# psoc4000s register map
Vendor: Infineon Technologies; Series: PSOC4000S; File version: 1.0
CPU: CM0PLUS r0p1, little endian, MPU, no FPU, VTOR, 2 interrupt priority bits, 16 interrupts
Registers are 32-bit, read-write, reset 0x0 unless marked. A register's access mark holds for its fields unless they carry their own. Offsets are from the block's base; [hi:lo] are bit positions; 'fields as' and 'values as' point back to an identical list; <NAME> marks a mode.

## LPCOMP — Low Power Comparators
Base 0x400C0000
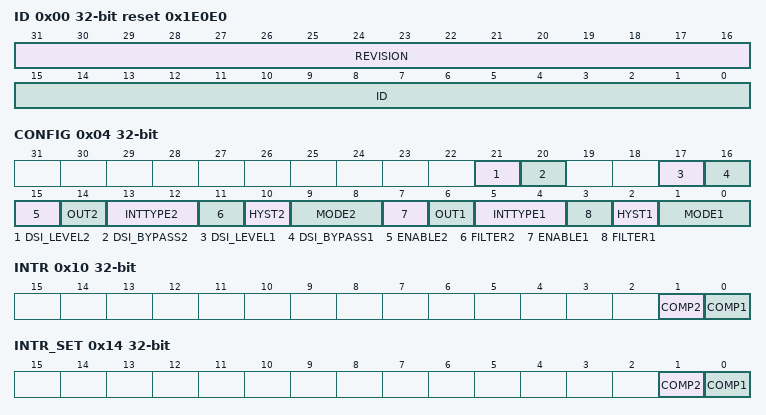
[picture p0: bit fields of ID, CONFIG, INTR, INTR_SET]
0x00 ID ro reset 0x1E0E0 — ID & Revision
  [31:16] REVISION — the version number is 0x0001
  [15:0] ID — the ID of LPCOMP peripheral is 0xE0E0
0x04 CONFIG — LPCOMP Configuration Register
  [21] DSI_LEVEL2 — Opamp2 comparator DSI (trigger) out level : 0=pulse, 1=level
  [20] DSI_BYPASS2 — Opamp2 bypass comparator output synchronization for DSI output: 0=synchronize (level or pulse), 1=bypass (output async) Note that in DeepSleep mode this bit needs to be set to observe the DSI output on the dedicated pin.
  [17] DSI_LEVEL1 — Opamp1 comparator DSI (trigger) out level : 0=pulse, 1=level
  [16] DSI_BYPASS1 — Opamp1 bypass comparator output synchronization for DSI output: 0=synchronize (level or pulse), 1=bypass (output async) Note that in DeepSleep mode this bit needs to be set to observe the DSI output on the dedicated pin.
  [15] ENABLE2 — Enable comparator #2
  [14] OUT2 ro — Current output value of the comparator.
  [13:12] INTTYPE2 — Sets which edge will trigger an IRQ
    0=DISABLE (Disabled, no interrupts will be detected); 1=RISING (Rising edge); 2=FALLING (Falling edge); 3=BOTH (Both rising and falling edges)
  [11] FILTER2
  [10] HYST2 — Add 10mV hysteresis to the comparator - 0: Enable Hysteresis - 1: Disable Hysteresis
  [9:8] MODE2 — Operating mode for the comparator
    0=SLOW (Slow operating mode (uses less power, <50uA)); 1=FAST (Fast operating mode (uses more power, <400uA)); 2=ULP (Ultra low power operting mode (uses ~2-4uA))
  [7] ENABLE1 — Enable comparator #1
  [6] OUT1 ro — Current output value of the comparator.
  [5:4] INTTYPE1 — Sets which edge will trigger an IRQ
    values as INTTYPE2
  [3] FILTER1
  [2] HYST1 — Add 10mV hysteresis to the comparator - 0: Enable Hysteresis - 1: Disable Hysteresis
  [1:0] MODE1 — Operating mode for the comparator
    values as MODE2
0x10 INTR — LPCOMP Interrupt request register
  [1] COMP2 write-1-clears — Comparator 2 Interrupt: hardware sets this interrupt when comparator 0 triggers. Write with '1' to clear bit.
  [0] COMP1 write-1-clears — Comparator 1 Interrupt: hardware sets this interrupt when comparator 0 triggers. Write with '1' to clear bit.
0x14 INTR_SET — LPCOMP Interrupt set register
  [1] COMP2 write-1-sets — Write with '1' to set corresponding bit in interrupt request register.
  [0] COMP1 write-1-sets — Write with '1' to set corresponding bit in interrupt request register.
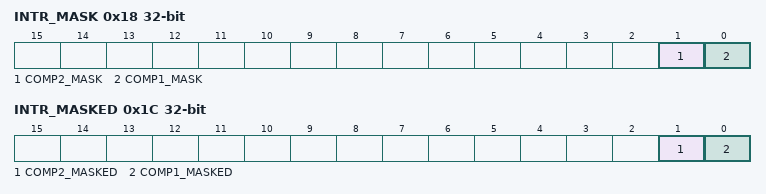
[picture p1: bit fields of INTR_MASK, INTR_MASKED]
0x18 INTR_MASK — LPCOMP Interrupt request mask
  [1] COMP2_MASK — Mask bit for corresponding bit in interrupt request register.
  [0] COMP1_MASK — Mask bit for corresponding bit in interrupt request register.
0x1C INTR_MASKED ro — LPCOMP Interrupt request masked
  [1] COMP2_MASKED — Logical and of corresponding request and mask bits.
  [0] COMP1_MASKED — Logical and of corresponding request and mask bits.
0xFF00 TRIM1 — LPCOMP Trim Register
  [4:0] COMP1_TRIMA — Trim A for Comparator #1
0xFF04 TRIM2 — LPCOMP Trim Register
  [4:0] COMP1_TRIMB — Trim B for Comparator #1
0xFF08 TRIM3 — LPCOMP Trim Register
  [4:0] COMP2_TRIMA — Trim A for Comparator #2
0xFF0C TRIM4 — LPCOMP Trim Register
  [4:0] COMP2_TRIMB — Trim B for Comparator #2

## SPCIF — Flash Control Interface
Base 0x40110000
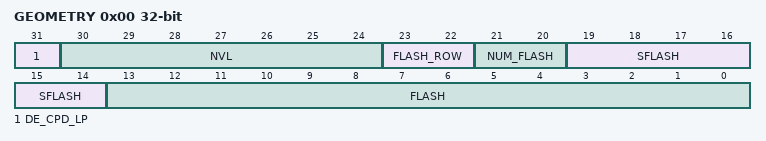
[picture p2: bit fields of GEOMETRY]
0x00 GEOMETRY (reset mask 0x80000000) — Flash/NVL geometry information
  [31] DE_CPD_LP — 0': SRAM busy wait loop has not been copied. '1': Busy wait loop has been written into SRAM.
  [30:24] NVL ro — NVLatch size in Byte multiples (chip dependent): '0': 0 Bytes '1': 1 Byte ... '127': 127 Bytes
  [23:22] FLASH_ROW ro — Page size in 64 Byte multiples (chip dependent): '0': 64 byte '1': 128 byte '2': 192 byte '3': 256 byte The page size is used to determine the number of Bytes in a page for Flash page based operations (e.g. PGM_PAGE). Note: the field name FLASH_ROW is misleading, as this field specifies the number of Bytes in a page, rather than the number of Bytes in a row. In a single plane flash macro architecture, a page consists of a single row. However, in a multi plane flash macro architecture, a page consists of multiple rows from different planes.
  [21:20] NUM_FLASH ro — Number of flash macros (chip dependent): '0': 1 flash macro '1': 2 flash macros '2': 3 flash macros '3': 4 flash macros
  [19:14] SFLASH ro — Supervisory flash capacity in 256 Byte multiples (chip dependent). If multiple flash macros are present, this field provides the supervisory flash capacity of all flash macros together: '0': 256 Bytes. '1': 2*256 Bytes. ... '63': 64*256 Bytes.
  [13:0] FLASH ro — Regular flash capacity in 256 Byte multiples (chip dependent). If multiple flash macros are present, this field provides the flash capacity of all flash macros together: '0': 256 Bytes. '1': 2*256 Bytes. ... '16383': 16384*256 Bytes.
0x1C NVL_WR_DATA — NVL write data register
  [7:0] DATA — Data to be written to NVLatch array
0x7F0 INTR — SPCIF interrupt request register
  [0] TIMER write-1-clears — Timer counter value reaches '0'. Set to '1', when event is detected. Write INTR field with '1', to clear bit. Write INTR_SET field with '1', to set bit.
0x7F4 INTR_SET — SPCIF interrupt set request register
  [0] TIMER write-1-sets — Write INTR_SET field with '1' to set corresponding INTR field.
0x7F8 INTR_MASK — SPCIF interrupt mask register
  [0] TIMER — Mask for corresponding field in INTR register.
0x7FC INTR_MASKED ro — SPCIF interrupt masked request register
  [0] TIMER — Logical and of corresponding request and mask fields.
